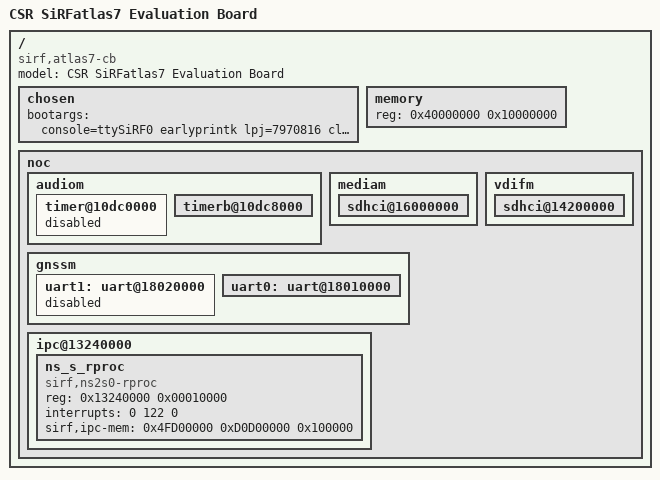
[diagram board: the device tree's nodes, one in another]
/*
 * DTS file for CSR SiRFatlas7 Evaluation Board
 *
 * Copyright (c) 2012 Cambridge Silicon Radio Limited, a CSR plc group company.
 *
 * Licensed under GPLv2 or later.
 */

/dts-v1/;

/include/ "atlas7.dtsi"

/ {
	model = "CSR SiRFatlas7 Evaluation Board";
	compatible = "sirf,atlas7-cb", "sirf,atlas7";

	chosen {
		bootargs = "console=ttySiRF0 earlyprintk lpj=7970816 clk_ignore_unused";
	};

	memory {
		device_type = "memory";
		reg = <0x40000000 0x10000000>; /* 256M for NS */
	};

	noc {
		audiom {
			timer@10dc0000 {
				status = "disabled";
			};
			timerb@10dc8000 {
				status = "okay";
			};
		};

                mediam {
                        sdhci@16000000 {
                                status = "okay";
                        };
                };

                vdifm {
                        sdhci@14200000 {
                                status = "okay";
                        };
                };

                gnssm {
                        uart1: uart@18020000 {
				status = "disabled";
                        };

                        uart0: uart@18010000 {
                                status = "okay";
                        };
                };

		ipc@13240000 {
			ns_s_rproc {
				compatible = "sirf,ns2s0-rproc";
				reg = <0x13240000 0x00010000>;
				interrupts = <0 122 0>;

				sirf,ipc-mem = <0x4FD00000 0xD0D00000 0x100000>;
			};
		};

	};

};
